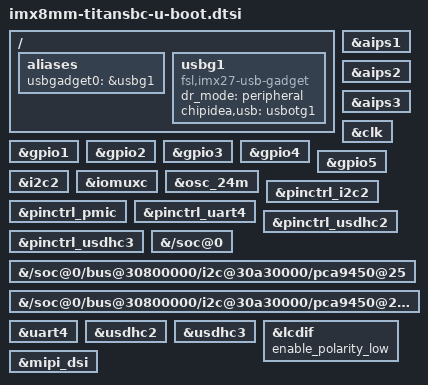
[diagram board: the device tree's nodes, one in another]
// SPDX-License-Identifier: GPL-2.0+
/*
 * Copyright 2020 Somlabs
 */

/ {
 	aliases {
		usbgadget0 = &usbg1;
	};

	usbg1: usbg1 {
		compatible = "fsl,imx27-usb-gadget";
		dr_mode = "peripheral";
		chipidea,usb = <&usbotg1>;
		status = "okay";
	};
};

&aips1 {
	bootph-pre-ram;
	bootph-all;
};

&aips2 {
	bootph-pre-ram;
};

&aips3 {
	bootph-pre-ram;
};

&clk {
	bootph-pre-ram;
	bootph-all;
	/delete-property/ assigned-clocks;
	/delete-property/ assigned-clock-parents;
	/delete-property/ assigned-clock-rates;
};

&gpio1 {
	bootph-pre-ram;
};

&gpio2 {
	bootph-pre-ram;
};

&gpio3 {
	bootph-pre-ram;
};

&gpio4 {
	bootph-pre-ram;
};

&gpio5 {
	bootph-pre-ram;
};

&i2c2 {
	bootph-pre-ram;
};

&iomuxc {
	bootph-pre-ram;
};

&osc_24m {
	bootph-pre-ram;
	bootph-all;
};

&pinctrl_i2c2 {
	bootph-pre-ram;
};

&pinctrl_pmic {
	bootph-pre-ram;
};

&pinctrl_uart4 {
	bootph-pre-ram;
};

&pinctrl_usdhc2 {
	bootph-pre-ram;
};

&pinctrl_usdhc3 {
	bootph-pre-ram;
};

&{/soc@0} {
	bootph-all;
	bootph-pre-ram;
};

&{/soc@0/bus@30800000/i2c@30a30000/pca9450@25} {
	bootph-pre-ram;
};

&{/soc@0/bus@30800000/i2c@30a30000/pca9450@25/regulators} {
	bootph-pre-ram;
};

&uart4 {
	bootph-pre-ram;
};

&usdhc2 {
	bootph-pre-ram;
};

&usdhc3 {
	bootph-pre-ram;
};

&lcdif {
	enable_polarity_low;
	/delete-property/ assigned-clocks;
	/delete-property/ assigned-clock-parents;
	/delete-property/ assigned-clock-rates;
};

&mipi_dsi {
	/delete-property/ assigned-clocks;
	/delete-property/ assigned-clock-parents;
	/delete-property/ assigned-clock-rates;
};
